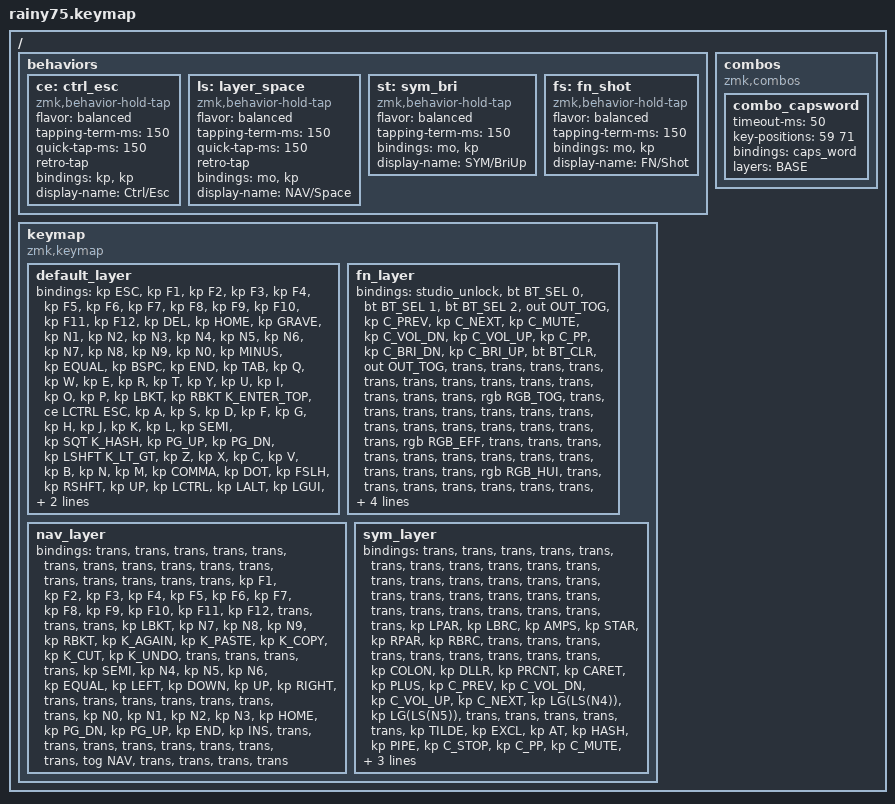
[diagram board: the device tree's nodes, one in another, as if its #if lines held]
/* Rainy 75 Pro — yd60mq keymap, ZMK edition
 *
 * Drop-in replacement for zmk/boards/rainy75/rainy75.keymap in
 * https://github.com/scholzri/rainy75-zmk (open ZMK port for the Rainy 75 Pro).
 * Build with `./build.sh -a --ansi` there — see ../zmk/README.md in this repo.
 *
 * This is the full yd60mq port that stock firmware + VIA could not express:
 *   - Caps      = Esc tap / Ctrl hold   (real mod-tap, tunable timing)
 *   - Space     = Space tap / NAV hold  (quick-tap so fast typing never eats spaces)
 *   - Right Ctrl= SYM hold              (the Right-Ctrl keycap types the symbol
 *   - Fn key    = Fn layer (RGB/BT/media) layer; the Fn keycap keeps the board's
 *                                        Rainy layer — RGB/BT/media/Studio, no keys)
 *   - all 18 yd60mq combos in firmware  (no Karabiner, any OS)
 * Layer numbers match the VIA port (0=base, 1=Fn, 2=NAV, 3=SYM) so
 * docs/cheatsheet.html still applies. Fn layer (RGB/BT/media) is unchanged
 * from the upstream rainy75-zmk keymap.
 */

#include <behaviors.dtsi>
#include <rainy_rgb.dtsi>
#include <dt-bindings/rainy_rgb.h>
#include <dt-bindings/zmk/keys.h>
#include <dt-bindings/zmk/bt.h>
#include <dt-bindings/zmk/outputs.h>

#define BASE 0
#define FN   1
#define NAV  2
#define SYM  3

/* ── Physical layout: ISO (default) or ANSI ──
 * Same convention as upstream: `./build.sh --ansi` defines RAINY75_ANSI for the
 * devicetree preprocessor. The binding count is identical either way (&none
 * still occupies the ISO <> slot), so combo key-positions below hold for both. */
#ifdef RAINY75_ANSI
#define K_ENTER_TOP  &kp BSLH   /* ISO Enter (top) -> ANSI backslash */
#define K_HASH       &kp RET    /* ISO #~ (NUHS)   -> ANSI wide Enter */
#define K_LT_GT      &none      /* ISO <> (NUBS)   -> absent on ANSI */
#define K_RALT       &none      /* pos 77: no key right of Space on ANSI
                                   (also no LED there — see led_map.c) */
#else
#define K_ENTER_TOP  &kp RET
#define K_HASH       &kp NUHS
#define K_LT_GT      &kp NUBS
#define K_RALT       &kp RALT
#endif

/ {
	/* Timing ported 1:1 from the yd60mq's tuned config.h:
	 *   TAPPING_TERM 150                          -> tapping-term-ms = <150>
	 *   PERMISSIVE_HOLD + IGNORE_MOD_TAP_INTERRUPT -> flavor = "balanced"
	 *   RETRO_TAPPING                              -> retro-tap
	 *   QUICK_TAP_TERM (QMK default = TAPPING_TERM) -> quick-tap-ms = <150>
	 *   COMBO_TERM 20                              -> combo timeout-ms = <20> */
	behaviors {
		/* Caps = LCTL_T(KC_ESC) from the yd60mq. "balanced" decides hold as
		 * soon as another key is pressed AND released while Caps is down;
		 * retro-tap still sends Esc when held past the term and released
		 * with no other key (RETRO_TAPPING). */
		ce: ctrl_esc {
			compatible = "zmk,behavior-hold-tap";
			#binding-cells = <2>;
			flavor = "balanced";
			tapping-term-ms = <150>;
			quick-tap-ms = <150>;
			retro-tap;
			bindings = <&kp>, <&kp>;
			display-name = "Ctrl/Esc";
		};

		/* Space = LT(NAV, KC_SPC). quick-tap-ms is the fix for the stock
		 * firmware's fixed tap/hold window eating quick spaces: any Space
		 * within 150 ms of the previous tap is always a tap (and
		 * tap-then-hold auto-repeats space). Raise tapping-term-ms if a
		 * held-space NAV still triggers too eagerly for your typing speed. */
		ls: layer_space {
			compatible = "zmk,behavior-hold-tap";
			#binding-cells = <2>;
			flavor = "balanced";
			tapping-term-ms = <150>;
			quick-tap-ms = <150>;
			retro-tap;
			bindings = <&mo>, <&kp>;
			display-name = "NAV/Space";
		};

		/* SYM key = hold SYM layer / tap = Brightness Up (C_BRI_UP consumer
		 * key; was the yd60mq's ⌘⇧4 SCR_SHOT macro — screenshots remain on
		 * SYM+; and SYM+'). NO retro-tap — a bare hold-then-release must not
		 * nudge the brightness. (The yd60mq's own bottom row made this key an
		 * LT(2,…) layer-tap too, so a tap action here is faithful, not a hack.) */
		st: sym_bri {
			compatible = "zmk,behavior-hold-tap";
			#binding-cells = <2>;
			flavor = "balanced";
			tapping-term-ms = <150>;
			bindings = <&mo>, <&kp>;
			display-name = "SYM/BriUp";
		};

		/* FN key = hold Fn layer (RGB/BT/media/Studio) / tap = macOS
		 * screenshot region-select (⌘⇧4 = LG(LS(N4)), the same keycode
		 * as SYM+; ). Same shape as `st`: balanced, NO retro-tap so a
		 * bare hold-then-release just opens the Fn layer and never fires
		 * a stray screenshot. */
		fs: fn_shot {
			compatible = "zmk,behavior-hold-tap";
			#binding-cells = <2>;
			flavor = "balanced";
			tapping-term-ms = <150>;
			bindings = <&mo>, <&kp>;
			display-name = "FN/Shot";
		};
	};

	/* ── The 18 yd60mq chords, firmware-level at last ──
	 * Key positions index the 83 bindings below, row-major:
	 * row0 0-14 · row1 15-29 · row2 30-43 · row3 44-58 · row4 59-72 · row5 73-82
	 * (letters: Q=31 W=32 E=33 R=34 · U=37 I=38 O=39 P=40 · A=45 S=46 D=47 F=48
	 *  H=50 J=51 K=52 L=53 ;=54 · Z=61 X=62 C=63 V=64 B=65 N=66 M=67 ,=68 .=69)
	 * Base layer only. timeout-ms = 20 is the yd60mq's tuned COMBO_TERM: a tight
	 * window so common letter pairs (we/er/sd/…) don't fire combos mid-word. If
	 * deliberate chords prove too hard to hit at 20 ms, add require-prior-idle-ms
	 * (fire only at the start of a word) rather than widening this term. */
	combos {
		compatible = "zmk,combos";   /* MUST be plural. "zmk,combo" (singular) is
		                                silently ignored by ZMK — no combo compiles
		                                in and none ever fire. THAT (not the 20 ms
		                                term) was the original "combos broken" bug. */
		#define CHORD(name, keys, out) \
			combo_##name { timeout-ms = <20>; key-positions = <keys>; \
				bindings = <out>; layers = <BASE>; };
		CHORD(qw, 31 32, &kp LPAR)   /* Q+W -> ( */
		CHORD(we, 32 33, &kp ESC)    /* W+E -> Esc */
		CHORD(er, 33 34, &kp RPAR)   /* E+R -> ) */
		CHORD(ui, 37 38, &kp GRAVE)  /* U+I -> ` */
		CHORD(io, 38 39, &kp DQT)    /* I+O -> " */
		CHORD(op, 39 40, &kp SQT)    /* O+P -> ' */
		CHORD(sd, 46 47, &kp BSPC)   /* S+D -> Backspace */
		CHORD(df, 47 48, &kp TAB)    /* D+F -> Tab */
		CHORD(hj, 50 51, &kp LT)     /* H+J -> < */
		CHORD(jk, 51 52, &kp COLON)  /* J+K -> : */
		CHORD(kl, 52 53, &kp PIPE)   /* K+L -> | */
		CHORD(lsemi, 53 54, &kp GT)  /* L+; -> > */
		CHORD(zx, 61 62, &kp EXCL)   /* Z+X -> ! */
		CHORD(xc, 62 63, &kp MINUS)  /* X+C -> - */
		CHORD(cv, 63 64, &kp UNDER)  /* C+V -> _ */
		CHORD(nm, 66 67, &kp QMARK)  /* N+M -> ? */
		CHORD(mcomma, 67 68, &kp BSLH)   /* M+, -> \ */
		CHORD(commadot, 68 69, &kp FSLH) /* ,+. -> / */
		#undef CHORD

		/* Both Shifts together -> Caps Word (types ONE_WORD_LIKE_THIS; ends on
		 * space/punctuation). Wider window than the letter chords — shifts are
		 * deliberate, not typed through. */
		combo_capsword {
			timeout-ms = <50>;
			key-positions = <59 71>;   /* LSHFT + RSHFT */
			bindings = <&caps_word>;
			layers = <BASE>;
		};
	};

	keymap {
		compatible = "zmk,keymap";

		default_layer {
			/* Layer 0 — stock Rainy 75 base, changed for the yd60mq port:
			 * Caps -> Esc tap / Ctrl hold · Space -> Space tap / NAV hold ·
			 * Right Ctrl -> SYM hold / tap = Brightness Up · Fn key -> Fn layer
			 * hold (board controls) / tap = macOS screenshot ⌘⇧4 · left mods are Ctrl-ALT-GUI
			 * (yd60mq / Mac order: Command next to Space — stock ships Ctrl-GUI-Alt
			 * and relied on its Mac-mode toggle, which ZMK doesn't have). */
			bindings = <
				&kp ESC   &kp F1   &kp F2   &kp F3  &kp F4  &kp F5  &kp F6  &kp F7  &kp F8  &kp F9    &kp F10   &kp F11   &kp F12   &kp DEL   &kp HOME
				&kp GRAVE &kp N1   &kp N2   &kp N3  &kp N4  &kp N5  &kp N6  &kp N7  &kp N8  &kp N9    &kp N0    &kp MINUS &kp EQUAL &kp BSPC  &kp END
				&kp TAB   &kp Q    &kp W    &kp E   &kp R   &kp T   &kp Y   &kp U   &kp I   &kp O     &kp P     &kp LBKT  &kp RBKT  K_ENTER_TOP
				&ce LCTRL ESC &kp A &kp S   &kp D   &kp F   &kp G   &kp H   &kp J   &kp K   &kp L     &kp SEMI  &kp SQT   K_HASH             &kp PG_UP &kp PG_DN
				&kp LSHFT K_LT_GT  &kp Z    &kp X   &kp C   &kp V   &kp B   &kp N   &kp M   &kp COMMA &kp DOT   &kp FSLH            &kp RSHFT &kp UP
				&kp LCTRL &kp LALT &kp LGUI                                          &ls NAV SPACE K_RALT &st SYM C_BRI_UP &fs FN LG(LS(N4)) &kp LEFT  &kp DOWN  &kp RIGHT
			>;
		};

		fn_layer {
			/* Layer 1 — Fn: RGB / Bluetooth / media, unchanged from upstream
			 * rainy75-zmk so all board controls keep working. NOTE: the trigger
			 * is the *Fn keycap* (the Right-Ctrl keycap is SYM; see layer 0).
			 * Fn+F1/F2/F3 = BT profile 1/2/3 · Fn+F4 = USB/BLE toggle ·
			 * Fn+Esc = Studio unlock · Fn+Bksp = RGB toggle · Fn+Enter = effect ·
			 * Fn+# = hue · Fn+arrows = brightness/speed. */
			bindings = <
				&studio_unlock &bt BT_SEL 0 &bt BT_SEL 1 &bt BT_SEL 2 &out OUT_TOG &kp C_PREV &kp C_NEXT &kp C_MUTE &kp C_VOL_DN &kp C_VOL_UP &kp C_PP &kp C_BRI_DN &kp C_BRI_UP &bt BT_CLR &out OUT_TOG
				&trans &trans &trans &trans &trans &trans &trans &trans &trans &trans &trans &trans &trans &rgb RGB_TOG &trans
				&trans &trans &trans &trans &trans &trans &trans &trans &trans &trans &trans &trans &trans &rgb RGB_EFF
				&trans &trans &trans &trans &trans &trans &trans &trans &trans &trans &trans &trans &rgb RGB_HUI        &trans &trans
				&trans &trans &trans &trans &trans &trans &rgb RGB_BAT &trans &trans &trans &trans &trans        &trans &rgb RGB_BRI
				&trans &trans &trans                                          &trans &trans &trans &trans        &rgb RGB_SPD &rgb RGB_BRD &rgb RGB_SPI
			>;
		};

		nav_layer {
			/* Layer 2 — NAV (hold Space), straight from the yd60mq:
			 * number row -> F1-F12 · QWERT -> [ 7 8 9 ] ·
			 * YUIOP -> Again/Paste/Copy/Cut/Undo · ASDFG -> ; 4 5 6 = ·
			 * HJKL -> arrows · ZXCVB -> 0 1 2 3 Home · NM,. -> PgDn PgUp End Ins
			 * SYM keycap (right of Space) -> latch NAV (the yd60mq's TT(1)):
			 * hold Space, tap the SYM key to lock NAV without holding; tap it
			 * again to exit. (Also stops a stray brightness bump mid-NAV.) */
			bindings = <
				&trans    &trans   &trans   &trans  &trans  &trans  &trans  &trans  &trans  &trans    &trans    &trans    &trans    &trans    &trans
				&trans    &kp F1   &kp F2   &kp F3  &kp F4  &kp F5  &kp F6  &kp F7  &kp F8  &kp F9    &kp F10   &kp F11   &kp F12   &trans    &trans
				&trans    &kp LBKT &kp N7   &kp N8  &kp N9  &kp RBKT &kp K_AGAIN &kp K_PASTE &kp K_COPY &kp K_CUT &kp K_UNDO &trans &trans   &trans
				&trans    &kp SEMI &kp N4   &kp N5  &kp N6  &kp EQUAL &kp LEFT &kp DOWN &kp UP &kp RIGHT &trans   &trans    &trans             &trans    &trans
				&trans    &trans   &kp N0   &kp N1  &kp N2  &kp N3  &kp HOME &kp PG_DN &kp PG_UP &kp END &kp INS &trans              &trans    &trans
				&trans    &trans   &trans                                            &trans    &trans   &tog NAV  &trans              &trans    &trans    &trans
			>;
		};

		sym_layer {
			/* Layer 3 — SYM (hold Right Ctrl), straight from the yd60mq:
			 * Tab QWERT -> ( { & * ) } · ASDFG -> : $ % ^ + ·
			 * HJKL -> Prev/Vol-/Vol+/Next · ZXCVB -> ~ ! @ # | ·
			 * NM, -> Stop/Play/Mute · ; ' -> macOS screenshot (Cmd-Shift-4/5) */
			bindings = <
				&trans    &trans   &trans   &trans  &trans  &trans  &trans  &trans  &trans  &trans    &trans    &trans    &trans    &trans    &trans
				&trans    &trans   &trans   &trans  &trans  &trans  &trans  &trans  &trans  &trans    &trans    &trans    &trans    &trans    &trans
				&kp LPAR  &kp LBRC &kp AMPS &kp STAR &kp RPAR &kp RBRC &trans &trans &trans &trans    &trans    &trans    &trans    &trans
				&trans    &kp COLON &kp DLLR &kp PRCNT &kp CARET &kp PLUS &kp C_PREV &kp C_VOL_DN &kp C_VOL_UP &kp C_NEXT &kp LG(LS(N4)) &kp LG(LS(N5)) &trans   &trans    &trans
				&trans    &trans   &kp TILDE &kp EXCL &kp AT &kp HASH &kp PIPE &kp C_STOP &kp C_PP &kp C_MUTE &trans &trans           &trans    &trans
				&trans    &trans   &trans                                            &trans    &trans   &trans    &trans              &trans    &trans    &trans
			>;
		};
	};
};
